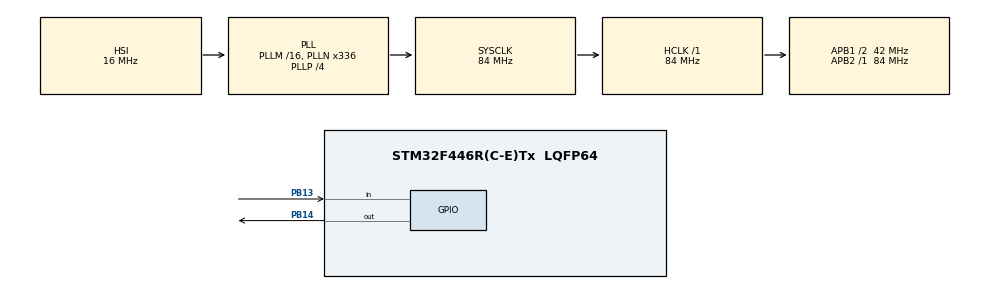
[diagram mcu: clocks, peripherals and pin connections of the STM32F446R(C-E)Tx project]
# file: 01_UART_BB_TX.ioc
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Mcu.Family=STM32F4
Mcu.Name=STM32F446R(C-E)Tx
Mcu.Package=LQFP64
NVIC.PriorityGroup=NVIC_PRIORITYGROUP_0
PB13.Signal=GPIO_Input
PB14.Signal=GPIO_Output
PH0-OSC_IN.Mode=HSE-External-Oscillator
PH0-OSC_IN.Signal=RCC_OSC_IN
PH1-OSC_OUT.Mode=HSE-External-Oscillator
PH1-OSC_OUT.Signal=RCC_OSC_OUT
ProjectManager.HeapSize=0x200
ProjectManager.StackSize=0x400
ProjectManager.TargetToolchain=STM32CubeIDE
RCC.AHBFreq_Value=84000000
RCC.APB1CLKDivider=RCC_HCLK_DIV2
RCC.APB1Freq_Value=42000000
RCC.APB1TimFreq_Value=84000000
RCC.APB2Freq_Value=84000000
RCC.APB2TimFreq_Value=84000000
RCC.CortexFreq_Value=84000000
RCC.FLatency-AdvancedSettings=FLASH_LATENCY_2
RCC.HCLKFreq_Value=84000000
RCC.HSE_VALUE=8000000
RCC.HSI_VALUE=16000000
RCC.LSE_VALUE=32768
RCC.PLLN=336
RCC.PLLP=RCC_PLLP_DIV4
RCC.SYSCLKFreq_VALUE=84000000
RCC.SYSCLKSource=RCC_SYSCLKSOURCE_PLLCLK
RCC.USBFreq_Value=168000000
RCC.VCOOutputFreq_Value=336000000
board=NUCLEO-F446RE

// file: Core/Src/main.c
/* USER CODE BEGIN Header */
/**
  ******************************************************************************
  * @file           : main.c
  * @brief          : Main program body
  ******************************************************************************
  * @attention
  *
  * Copyright (c) 2026 STMicroelectronics.
  * All rights reserved.
  *
  * This software is licensed under terms that can be found in the LICENSE file
  * in the root directory of this software component.
  * If no LICENSE file comes with this software, it is provided AS-IS.
  *
  ******************************************************************************
  */
/* USER CODE END Header */
#include "main.h"

/* USER CODE BEGIN PV */
volatile uint8_t rx;
/* USER CODE END PV */

void SystemClock_Config(void);
static void MX_GPIO_Init(void);
/* USER CODE BEGIN PFP */
void DWT_Init(void);
void BitDelay(void);
void UART_StartBit(void);
void UART_SendByte(uint8_t);
void UART_SendString(char*);
uint8_t UART_ReceiveByte(void);
void BitDelay_1_5(void);
/* USER CODE END PFP */

int main(void)
{

  /* MCU Configuration--------------------------------------------------------*/

  /* Reset of all peripherals, Initializes the Flash interface and the Systick. */
  HAL_Init();

  /* Configure the system clock */
  SystemClock_Config();

  /* Initialize all configured peripherals */
  MX_GPIO_Init();
  /* USER CODE BEGIN 2 */
  DWT_Init();

  /* USER CODE END 2 */

  /* Infinite loop */
  while (1)
  {

    /* USER CODE BEGIN 3 */
	  rx = UART_ReceiveByte();

	     UART_SendByte(rx-1);

  }
  /* USER CODE END 3 */
}

void SystemClock_Config(void)
{
  RCC_OscInitTypeDef RCC_OscInitStruct = {0};
  RCC_ClkInitTypeDef RCC_ClkInitStruct = {0};

  /** Configure the main internal regulator output voltage
  */
  __HAL_RCC_PWR_CLK_ENABLE();
  __HAL_PWR_VOLTAGESCALING_CONFIG(PWR_REGULATOR_VOLTAGE_SCALE3);

  /** Initializes the RCC Oscillators according to the specified parameters
  * in the RCC_OscInitTypeDef structure.
  */
  RCC_OscInitStruct.OscillatorType = RCC_OSCILLATORTYPE_HSI;
  RCC_OscInitStruct.HSIState = RCC_HSI_ON;
  RCC_OscInitStruct.HSICalibrationValue = RCC_HSICALIBRATION_DEFAULT;
  RCC_OscInitStruct.PLL.PLLState = RCC_PLL_ON;
  RCC_OscInitStruct.PLL.PLLSource = RCC_PLLSOURCE_HSI;
  RCC_OscInitStruct.PLL.PLLM = 16;
  RCC_OscInitStruct.PLL.PLLN = 336;
  RCC_OscInitStruct.PLL.PLLP = RCC_PLLP_DIV4;
  RCC_OscInitStruct.PLL.PLLQ = 2;
  RCC_OscInitStruct.PLL.PLLR = 2;
  if (HAL_RCC_OscConfig(&RCC_OscInitStruct) != HAL_OK)
  {
    Error_Handler();
  }

  /** Initializes the CPU, AHB and APB buses clocks
  */
  RCC_ClkInitStruct.ClockType = RCC_CLOCKTYPE_HCLK|RCC_CLOCKTYPE_SYSCLK
                              |RCC_CLOCKTYPE_PCLK1|RCC_CLOCKTYPE_PCLK2;
  RCC_ClkInitStruct.SYSCLKSource = RCC_SYSCLKSOURCE_PLLCLK;
  RCC_ClkInitStruct.AHBCLKDivider = RCC_SYSCLK_DIV1;
  RCC_ClkInitStruct.APB1CLKDivider = RCC_HCLK_DIV2;
  RCC_ClkInitStruct.APB2CLKDivider = RCC_HCLK_DIV1;

  if (HAL_RCC_ClockConfig(&RCC_ClkInitStruct, FLASH_LATENCY_2) != HAL_OK)
  {
    Error_Handler();
  }
}

static void MX_GPIO_Init(void)
{
  GPIO_InitTypeDef GPIO_InitStruct = {0};

  /* GPIO Ports Clock Enable */
  __HAL_RCC_GPIOH_CLK_ENABLE();
  __HAL_RCC_GPIOB_CLK_ENABLE();

  /*Configure GPIO pin Output Level */
  HAL_GPIO_WritePin(GPIOB, GPIO_PIN_14, GPIO_PIN_RESET);

  /*Configure GPIO pin : PB13 */
  GPIO_InitStruct.Pin = GPIO_PIN_13;
  GPIO_InitStruct.Mode = GPIO_MODE_INPUT;
  GPIO_InitStruct.Pull = GPIO_PULLUP;
  HAL_GPIO_Init(GPIOB, &GPIO_InitStruct);

  /*Configure GPIO pin : PB14 */
  GPIO_InitStruct.Pin = GPIO_PIN_14;
  GPIO_InitStruct.Mode = GPIO_MODE_OUTPUT_PP;
  GPIO_InitStruct.Pull = GPIO_NOPULL;
  GPIO_InitStruct.Speed = GPIO_SPEED_FREQ_HIGH;
  HAL_GPIO_Init(GPIOB, &GPIO_InitStruct);

}

/* USER CODE BEGIN 4 */
void DWT_Init(void)
{
    CoreDebug->DEMCR |= CoreDebug_DEMCR_TRCENA_Msk;
    DWT->CYCCNT = 0;
    DWT->CTRL |= DWT_CTRL_CYCCNTENA_Msk;
}

void BitDelay(void)
{
    uint32_t start = DWT->CYCCNT;

    while ((DWT->CYCCNT - start) < 8736)
    {
    }
}

void UART_StartBit(void)
{
    HAL_GPIO_WritePin(GPIOB, GPIO_PIN_14, GPIO_PIN_RESET);
    BitDelay();

    HAL_GPIO_WritePin(GPIOB, GPIO_PIN_14, GPIO_PIN_SET);
}

void UART_SendByte(uint8_t data)
{
    /* Start bit */
    HAL_GPIO_WritePin(GPIOB, GPIO_PIN_14, GPIO_PIN_RESET);
    BitDelay();

    /* 8 data bits (LSB first) */
    for(uint8_t i = 0; i < 8; i++)
    {
        if(data & (1 << i))
        {
            HAL_GPIO_WritePin(GPIOB, GPIO_PIN_14, GPIO_PIN_SET);
        }
        else
        {
            HAL_GPIO_WritePin(GPIOB, GPIO_PIN_14, GPIO_PIN_RESET);
        }

        BitDelay();
    }

    /* Stop bit */
    HAL_GPIO_WritePin(GPIOB, GPIO_PIN_14, GPIO_PIN_SET);
    BitDelay();
}

void UART_SendString(char *str)
{
    while(*str)
    {
        UART_SendByte(*str++);
    }
}

uint8_t UART_ReceiveByte(void)
{
    uint8_t data = 0;

    /* Wait for start bit */
    while(HAL_GPIO_ReadPin(GPIOB, GPIO_PIN_13) == GPIO_PIN_SET);

    /* Move to center of D0 */
    BitDelay_1_5();

    /* Read 8 bits */
    for(uint8_t i = 0; i < 8; i++)
    {
        if(HAL_GPIO_ReadPin(GPIOB, GPIO_PIN_13) == GPIO_PIN_SET)
        {
            data |= (1 << i);
        }

        BitDelay();
    }

    /* Optional stop bit check */
    if(HAL_GPIO_ReadPin(GPIOB, GPIO_PIN_13) == GPIO_PIN_RESET)
    {
        /* Framing error */
    }

    return data;
}
void BitDelay_1_5(void)
{
	//This function is to plot the value after the start bit ... usually the bit is plotted in the middle
    uint32_t start = DWT->CYCCNT;

    while((DWT->CYCCNT - start) < 13104) // 8736 * 1.5
    {
    }
}
/* USER CODE END 4 */

void Error_Handler(void)
{
  __disable_irq();
  while (1)
  {
  }
}
